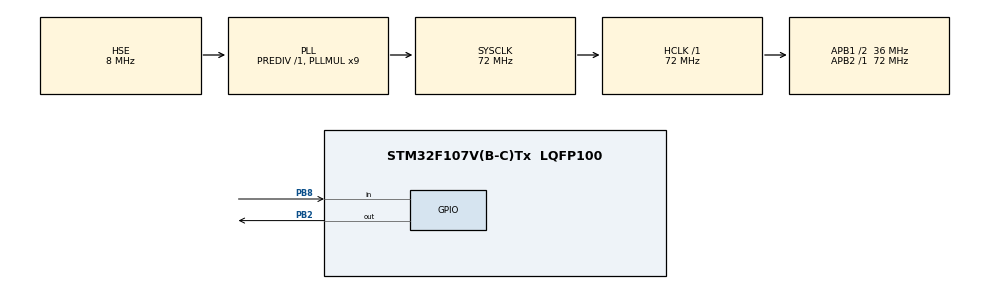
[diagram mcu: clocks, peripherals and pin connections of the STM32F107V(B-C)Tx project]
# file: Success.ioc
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Mcu.Family=STM32F1
Mcu.Name=STM32F107V(B-C)Tx
Mcu.Package=LQFP100
NVIC.PriorityGroup=NVIC_PRIORITYGROUP_4
NVIC.TIM1_UP_IRQn=true\:0\:0\:false\:false\:true\:true\:true\:true
OSC_IN.Mode=HSE-External-Oscillator
OSC_IN.Signal=RCC_OSC_IN
OSC_OUT.Mode=HSE-External-Oscillator
OSC_OUT.Signal=RCC_OSC_OUT
PA13.Mode=Serial_Wire
PA13.Signal=SYS_JTMS-SWDIO
PA14.Mode=Serial_Wire
PA14.Signal=SYS_JTCK-SWCLK
PB2.Signal=GPIO_Output
PB8.Signal=GPIO_Input
PC14-OSC32_IN.Mode=LSE-External-Oscillator
PC14-OSC32_IN.Signal=RCC_OSC32_IN
PC15-OSC32_OUT.Mode=LSE-External-Oscillator
PC15-OSC32_OUT.Signal=RCC_OSC32_OUT
ProjectManager.HeapSize=0x200
ProjectManager.StackSize=0x400
ProjectManager.TargetToolchain=Makefile
RCC.AHBFreq_Value=72000000
RCC.APB1CLKDivider=RCC_HCLK_DIV2
RCC.APB1Freq_Value=36000000
RCC.APB1TimFreq_Value=72000000
RCC.APB2Freq_Value=72000000
RCC.APB2TimFreq_Value=72000000
RCC.HCLKFreq_Value=72000000
RCC.PLLMUL=RCC_PLL_MUL9
RCC.PLLSourceVirtual=RCC_PLLSOURCE_HSE
RCC.SYSCLKFreq_VALUE=72000000
RCC.SYSCLKSource=RCC_SYSCLKSOURCE_PLLCLK
RCC.USBFreq_Value=48000000
TIM1.Prescaler=71
VP_TIM1_VS_ClockSourceINT.Mode=Internal
board=custom

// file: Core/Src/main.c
/* USER CODE BEGIN Header */
/**
  ******************************************************************************
  * @file           : main.c
  * @brief          : Main program body
  ******************************************************************************
  * @attention
  *
  * Copyright (c) 2024 STMicroelectronics.
  * All rights reserved.
  *
  * This software is licensed under terms that can be found in the LICENSE file
  * in the root directory of this software component.
  * If no LICENSE file comes with this software, it is provided AS-IS.
  *
  ******************************************************************************
  */
/* USER CODE END Header */
#include "main.h"
#include "tim.h"
#include "gpio.h"

/* USER CODE BEGIN Includes */
#include "DHT.h"
#include <stdio.h>
#include <string.h>
/* USER CODE END Includes */

void SystemClock_Config(void);

/* USER CODE BEGIN 0 */
#define    DWT_CYCCNT    *(volatile unsigned long *)0xE0001004
#define    DWT_CONTROL   *(volatile unsigned long *)0xE0001000
#define    SCB_DEMCR     *(volatile unsigned long *)0xE000EDFC

void delay_us(uint32_t us)
{
	int32_t us_count_tick =  us * (SystemCoreClock/1000000);
	//разрешаем использовать счётчик
	SCB_DEMCR |= CoreDebug_DEMCR_TRCENA_Msk;
        //обнуляем значение счётного регистра
	DWT_CYCCNT  = 0;
        //запускаем счётчик
	DWT_CONTROL |= DWT_CTRL_CYCCNTENA_Msk;
	while(DWT_CYCCNT < us_count_tick);
        //останавливаем счётчик
	DWT_CONTROL &= ~DWT_CTRL_CYCCNTENA_Msk;

}
//////////////////////////////
void delay_ms(uint32_t ms)
{
	int32_t ms_count_tick =  ms * (SystemCoreClock/1000);
	//разрешаем использовать счётчик
	SCB_DEMCR |= CoreDebug_DEMCR_TRCENA_Msk;
         //обнуляем значение счётного регистра
	DWT_CYCCNT  = 0;
        //запускаем счётчик
	DWT_CONTROL|= DWT_CTRL_CYCCNTENA_Msk;
	while(DWT_CYCCNT < ms_count_tick);
        //останавливаем счётчик
	DWT_CONTROL &= ~DWT_CTRL_CYCCNTENA_Msk;

}
static DHT_sensor livingRoom = {GPIOB, GPIO_PIN_8, DHT11, GPIO_NOPULL};
/* USER CODE END 0 */

int main(void)
{

  /* MCU Configuration--------------------------------------------------------*/

  /* Reset of all peripherals, Initializes the Flash interface and the Systick. */
  HAL_Init();

  /* Configure the system clock */
  SystemClock_Config();

  /* Initialize all configured peripherals */
  MX_GPIO_Init();
  MX_TIM1_Init();

  /* Infinite loop */
  /* USER CODE BEGIN WHILE */
  while (1)
  {//Буффер для печати текста
    char msg[40];
    //Получение данных с датчика
    DHT_data d = DHT_getData(&livingRoom);
    //Печать данных в буффер
    sprintf(msg, "\fLiving room: Temp %d°C, Hum %d%%", (uint8_t)d.temp, (uint8_t)d.hum);
    //Отправка текста в UART
    //HAL_UART_Transmit(&huart2, (uint8_t*)msg, strlen(msg), 0xFF);
    //HAL_GPIO_WritePin(GPIOB, GPIO_PIN_2, 1);
    //delay_ms(5000);
    //HAL_GPIO_WritePin(GPIOB, GPIO_PIN_2, 0);
    //delay_ms(5000);
    /* USER CODE END WHILE */

  }
}

void SystemClock_Config(void)
{
  RCC_OscInitTypeDef RCC_OscInitStruct = {0};
  RCC_ClkInitTypeDef RCC_ClkInitStruct = {0};

  /** Initializes the RCC Oscillators according to the specified parameters
  * in the RCC_OscInitTypeDef structure.
  */
  RCC_OscInitStruct.OscillatorType = RCC_OSCILLATORTYPE_HSE;
  RCC_OscInitStruct.HSEState = RCC_HSE_ON;
  RCC_OscInitStruct.HSEPredivValue = RCC_HSE_PREDIV_DIV1;
  RCC_OscInitStruct.HSIState = RCC_HSI_ON;
  RCC_OscInitStruct.Prediv1Source = RCC_PREDIV1_SOURCE_HSE;
  RCC_OscInitStruct.PLL.PLLState = RCC_PLL_ON;
  RCC_OscInitStruct.PLL.PLLSource = RCC_PLLSOURCE_HSE;
  RCC_OscInitStruct.PLL.PLLMUL = RCC_PLL_MUL9;
  RCC_OscInitStruct.PLL2.PLL2State = RCC_PLL_NONE;
  if (HAL_RCC_OscConfig(&RCC_OscInitStruct) != HAL_OK)
  {
    Error_Handler();
  }

  /** Initializes the CPU, AHB and APB buses clocks
  */
  RCC_ClkInitStruct.ClockType = RCC_CLOCKTYPE_HCLK|RCC_CLOCKTYPE_SYSCLK
                              |RCC_CLOCKTYPE_PCLK1|RCC_CLOCKTYPE_PCLK2;
  RCC_ClkInitStruct.SYSCLKSource = RCC_SYSCLKSOURCE_PLLCLK;
  RCC_ClkInitStruct.AHBCLKDivider = RCC_SYSCLK_DIV1;
  RCC_ClkInitStruct.APB1CLKDivider = RCC_HCLK_DIV2;
  RCC_ClkInitStruct.APB2CLKDivider = RCC_HCLK_DIV1;

  if (HAL_RCC_ClockConfig(&RCC_ClkInitStruct, FLASH_LATENCY_2) != HAL_OK)
  {
    Error_Handler();
  }

  /** Configure the Systick interrupt time
  */
  __HAL_RCC_PLLI2S_ENABLE();
}

void Error_Handler(void)
{
  __disable_irq();
  while (1)
  {
  }
}
